VERSION ""

NS_ :

BS_:

BU_:

BO_ 3221225472 VECTOR__INDEPENDENT_SIG_MSG: 0 Vector__XXX
 SG_ Message_Protection_Counter_8bit : 0|8@1+ (1,0) [0|0] "" Vector__XXX
 SG_ Message_Protection_Counter_12bit : 0|12@1+ (1,0) [0|0] "" Vector__XXX

BO_ 500 Message_E: 20 Vector__XXX
 SG_ Message_Protection_Counter_8bit : 128|8@1+ (1,0) [0|0] "" Vector__XXX
 SG_ Signal_Step_Counter : 64|64@1- (1,0) [-1.7E+308|1.7E+308] "N" Vector__XXX
 SG_ Signal_PWM : 0|64@1- (1,0) [-1.7E+308|1.7E+308] "N" Vector__XXX

BO_ 300 Message_C: 12 Vector__XXX
 SG_ Message_Protection_Counter_12bit : 64|12@1+ (1,0) [0|0] "" Vector__XXX
 SG_ Message_Protection_CRC16_ARC : 76|16@1+ (1,0) [0|0] "" Vector__XXX
 SG_ Signal_Sine_Shifted : 0|64@1- (1,0) [-1.7E+308|1.7E+308] "V" Vector__XXX

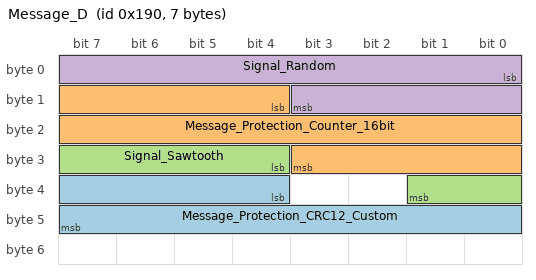
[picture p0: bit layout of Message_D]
BO_ 400 Message_D: 7 Vector__XXX
 SG_ Message_Protection_CRC12_Custom : 36|12@1+ (1,0) [0|0] "" Vector__XXX
 SG_ Message_Protection_Counter_16bit : 12|16@1+ (1,0) [0|0] "" Vector__XXX
 SG_ Signal_Sawtooth : 28|6@1- (1,0) [-128|127] "" Vector__XXX
 SG_ Signal_Random : 0|12@1+ (1,0) [0|65535] "degC" Vector__XXX

BO_ 200 Message_B: 12 Vector__XXX
 SG_ Message_Protection_CRC8_0x2F : 64|8@1+ (1,0) [0|0] "" Vector__XXX
 SG_ Signal_Sine : 0|64@1- (1,0) [-1.7E+308|1.7E+308] "V" Vector__XXX

BO_ 100 Message_A: 20 Vector__XXX
 SG_ Message_Protection_Counter_8bit : 128|8@1+ (1,0) [0|0] "" Vector__XXX
 SG_ Signal_Step_Counter : 64|64@1- (1,0) [-1.7E+308|1.7E+308] "N" Vector__XXX
 SG_ Signal_PWM : 0|64@1- (1,0) [-1.7E+308|1.7E+308] "N" Vector__XXX

CM_ BO_ 3221225472 "This is a message for not used signals, created by Vector CANdb++ DBC OLE DB Provider.";
BA_DEF_ BO_  "CANFD_BRS" ENUM  "0","1";
BA_DEF_  "DBName" STRING ;
BA_DEF_  "BusType" STRING ;
BA_DEF_ BO_  "VFrameFormat" ENUM  "StandardCAN","ExtendedCAN","reserved","reserved","reserved","reserved","reserved","reserved","reserved","reserved","reserved","reserved","reserved","reserved","StandardCAN_FD","ExtendedCAN_FD";
BA_DEF_DEF_  "CANFD_BRS" "1";
BA_DEF_DEF_  "DBName" "";
BA_DEF_DEF_  "BusType" "";
BA_DEF_DEF_  "VFrameFormat" "StandardCAN";
BA_ "BusType" "CAN FD";
BA_ "DBName" "CANFDDatabase";
BA_ "VFrameFormat" BO_ 500 14;
BA_ "VFrameFormat" BO_ 300 14;
BA_ "VFrameFormat" BO_ 400 14;
BA_ "VFrameFormat" BO_ 200 14;
BA_ "VFrameFormat" BO_ 100 14;
SIG_VALTYPE_ 500 Signal_Step_Counter : 2;
SIG_VALTYPE_ 500 Signal_PWM : 2;
SIG_VALTYPE_ 300 Signal_Sine_Shifted : 2;
SIG_VALTYPE_ 200 Signal_Sine : 2;
SIG_VALTYPE_ 100 Signal_Step_Counter : 2;
SIG_VALTYPE_ 100 Signal_PWM : 2;
